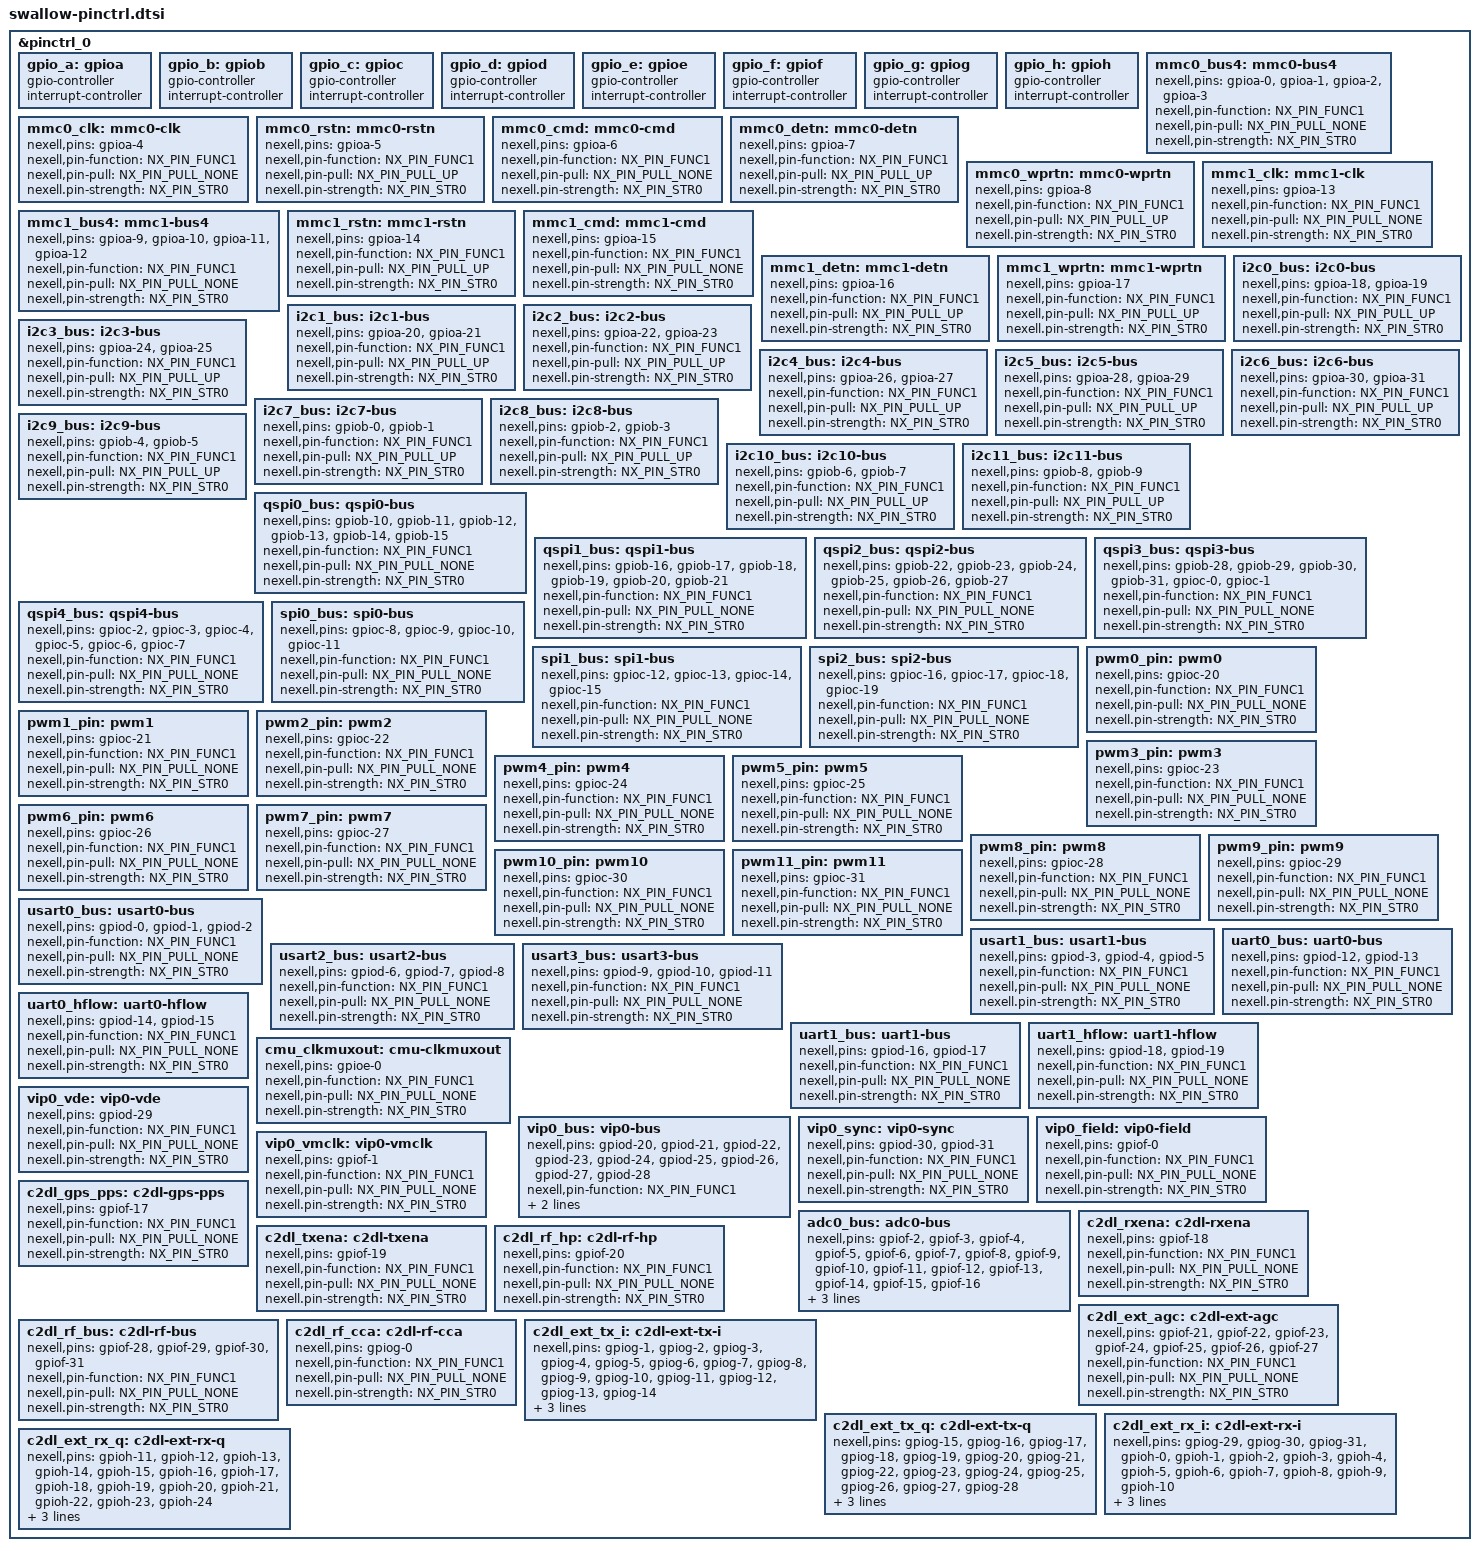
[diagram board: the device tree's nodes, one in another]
/*
 * SPDX-License-Identifier: (GPL-2.0+ OR MIT)
 *
 * Copyright (C) 2018  Nexell Co., Ltd.
 * Author: Sungwoo, Park <swpark@nexell.co.kr>
 */
 #include <dt-bindings/pinctrl/nexell.h>

 &pinctrl_0 {
	gpio_a: gpioa {
		gpio-controller;
		#gpio-cells = <2>;

		interrupt-controller;
		#interrupt-cells = <2>;
	};

	gpio_b: gpiob {
		gpio-controller;
		#gpio-cells = <2>;

		interrupt-controller;
		#interrupt-cells = <2>;
	};

	gpio_c: gpioc {
		gpio-controller;
		#gpio-cells = <2>;

		interrupt-controller;
		#interrupt-cells = <2>;
	};

	gpio_d: gpiod {
		gpio-controller;
		#gpio-cells = <2>;

		interrupt-controller;
		#interrupt-cells = <2>;
	};

	gpio_e: gpioe {
		gpio-controller;
		#gpio-cells = <2>;

		interrupt-controller;
		#interrupt-cells = <2>;
	};

	gpio_f: gpiof {
		gpio-controller;
		#gpio-cells = <2>;

		interrupt-controller;
		#interrupt-cells = <2>;
	};

	gpio_g: gpiog {
		gpio-controller;
		#gpio-cells = <2>;

		interrupt-controller;
		#interrupt-cells = <2>;
	};

	gpio_h: gpioh {
		gpio-controller;
		#gpio-cells = <2>;

		interrupt-controller;
		#interrupt-cells = <2>;
	};

	mmc0_bus4: mmc0-bus4 {
		nexell,pins = "gpioa-0", "gpioa-1", "gpioa-2", "gpioa-3";
		nexell,pin-function = <NX_PIN_FUNC1>;
		nexell,pin-pull = <NX_PIN_PULL_NONE>;
		nexell,pin-strength = <NX_PIN_STR0>;
	};

	mmc0_clk: mmc0-clk {
		nexell,pins = "gpioa-4";
		nexell,pin-function = <NX_PIN_FUNC1>;
		nexell,pin-pull = <NX_PIN_PULL_NONE>;
		nexell.pin-strength = <NX_PIN_STR0>;
	};

	mmc0_rstn: mmc0-rstn {
		nexell,pins = "gpioa-5";
		nexell,pin-function = <NX_PIN_FUNC1>;
		nexell,pin-pull = <NX_PIN_PULL_UP>;
		nexell.pin-strength = <NX_PIN_STR0>;
	};

	mmc0_cmd: mmc0-cmd {
		nexell,pins = "gpioa-6";
		nexell,pin-function = <NX_PIN_FUNC1>;
		nexell,pin-pull = <NX_PIN_PULL_NONE>;
		nexell.pin-strength = <NX_PIN_STR0>;
	};

	mmc0_detn: mmc0-detn {
		nexell,pins = "gpioa-7";
		nexell,pin-function = <NX_PIN_FUNC1>;
		nexell,pin-pull = <NX_PIN_PULL_UP>;
		nexell.pin-strength = <NX_PIN_STR0>;
	};

	mmc0_wprtn: mmc0-wprtn {
		nexell,pins = "gpioa-8";
		nexell,pin-function = <NX_PIN_FUNC1>;
		nexell,pin-pull = <NX_PIN_PULL_UP>;
		nexell.pin-strength = <NX_PIN_STR0>;
	};

	mmc1_bus4: mmc1-bus4 {
		nexell,pins = "gpioa-9", "gpioa-10", "gpioa-11", "gpioa-12";
		nexell,pin-function = <NX_PIN_FUNC1>;
		nexell,pin-pull = <NX_PIN_PULL_NONE>;
		nexell,pin-strength = <NX_PIN_STR0>;
	};

	mmc1_clk: mmc1-clk {
		nexell,pins = "gpioa-13";
		nexell,pin-function = <NX_PIN_FUNC1>;
		nexell,pin-pull = <NX_PIN_PULL_NONE>;
		nexell.pin-strength = <NX_PIN_STR0>;
	};

	mmc1_rstn: mmc1-rstn {
		nexell,pins = "gpioa-14";
		nexell,pin-function = <NX_PIN_FUNC1>;
		nexell,pin-pull = <NX_PIN_PULL_UP>;
		nexell.pin-strength = <NX_PIN_STR0>;
	};

	mmc1_cmd: mmc1-cmd {
		nexell,pins = "gpioa-15";
		nexell,pin-function = <NX_PIN_FUNC1>;
		nexell,pin-pull = <NX_PIN_PULL_NONE>;
		nexell.pin-strength = <NX_PIN_STR0>;
	};

	mmc1_detn: mmc1-detn {
		nexell,pins = "gpioa-16";
		nexell,pin-function = <NX_PIN_FUNC1>;
		nexell,pin-pull = <NX_PIN_PULL_UP>;
		nexell.pin-strength = <NX_PIN_STR0>;
	};

	mmc1_wprtn: mmc1-wprtn {
		nexell,pins = "gpioa-17";
		nexell,pin-function = <NX_PIN_FUNC1>;
		nexell,pin-pull = <NX_PIN_PULL_UP>;
		nexell.pin-strength = <NX_PIN_STR0>;
	};

	i2c0_bus: i2c0-bus {
		nexell,pins = "gpioa-18", "gpioa-19";
		nexell,pin-function = <NX_PIN_FUNC1>;
		nexell,pin-pull = <NX_PIN_PULL_UP>;
		nexell.pin-strength = <NX_PIN_STR0>;
	};

	i2c1_bus: i2c1-bus {
		nexell,pins = "gpioa-20", "gpioa-21";
		nexell,pin-function = <NX_PIN_FUNC1>;
		nexell,pin-pull = <NX_PIN_PULL_UP>;
		nexell.pin-strength = <NX_PIN_STR0>;
	};

	i2c2_bus: i2c2-bus {
		nexell,pins = "gpioa-22", "gpioa-23";
		nexell,pin-function = <NX_PIN_FUNC1>;
		nexell,pin-pull = <NX_PIN_PULL_UP>;
		nexell.pin-strength = <NX_PIN_STR0>;
	};

	i2c3_bus: i2c3-bus {
		nexell,pins = "gpioa-24", "gpioa-25";
		nexell,pin-function = <NX_PIN_FUNC1>;
		nexell,pin-pull = <NX_PIN_PULL_UP>;
		nexell.pin-strength = <NX_PIN_STR0>;
	};

	i2c4_bus: i2c4-bus {
		nexell,pins = "gpioa-26", "gpioa-27";
		nexell,pin-function = <NX_PIN_FUNC1>;
		nexell,pin-pull = <NX_PIN_PULL_UP>;
		nexell.pin-strength = <NX_PIN_STR0>;
	};

	i2c5_bus: i2c5-bus {
		nexell,pins = "gpioa-28", "gpioa-29";
		nexell,pin-function = <NX_PIN_FUNC1>;
		nexell,pin-pull = <NX_PIN_PULL_UP>;
		nexell.pin-strength = <NX_PIN_STR0>;
	};

	i2c6_bus: i2c6-bus {
		nexell,pins = "gpioa-30", "gpioa-31";
		nexell,pin-function = <NX_PIN_FUNC1>;
		nexell,pin-pull = <NX_PIN_PULL_UP>;
		nexell.pin-strength = <NX_PIN_STR0>;
	};

	i2c7_bus: i2c7-bus {
		nexell,pins = "gpiob-0", "gpiob-1";
		nexell,pin-function = <NX_PIN_FUNC1>;
		nexell,pin-pull = <NX_PIN_PULL_UP>;
		nexell.pin-strength = <NX_PIN_STR0>;
	};

	i2c8_bus: i2c8-bus {
		nexell,pins = "gpiob-2", "gpiob-3";
		nexell,pin-function = <NX_PIN_FUNC1>;
		nexell,pin-pull = <NX_PIN_PULL_UP>;
		nexell.pin-strength = <NX_PIN_STR0>;
	};

	i2c9_bus: i2c9-bus {
		nexell,pins = "gpiob-4", "gpiob-5";
		nexell,pin-function = <NX_PIN_FUNC1>;
		nexell,pin-pull = <NX_PIN_PULL_UP>;
		nexell.pin-strength = <NX_PIN_STR0>;
	};

	i2c10_bus: i2c10-bus {
		nexell,pins = "gpiob-6", "gpiob-7";
		nexell,pin-function = <NX_PIN_FUNC1>;
		nexell,pin-pull = <NX_PIN_PULL_UP>;
		nexell.pin-strength = <NX_PIN_STR0>;
	};

	i2c11_bus: i2c11-bus {
		nexell,pins = "gpiob-8", "gpiob-9";
		nexell,pin-function = <NX_PIN_FUNC1>;
		nexell,pin-pull = <NX_PIN_PULL_UP>;
		nexell.pin-strength = <NX_PIN_STR0>;
	};

	qspi0_bus: qspi0-bus {
		nexell,pins = "gpiob-10", "gpiob-11", "gpiob-12", "gpiob-13",
		"gpiob-14", "gpiob-15";
		nexell,pin-function = <NX_PIN_FUNC1>;
		nexell,pin-pull = <NX_PIN_PULL_NONE>;
		nexell.pin-strength = <NX_PIN_STR0>;
	};

	qspi1_bus: qspi1-bus {
		nexell,pins = "gpiob-16", "gpiob-17", "gpiob-18", "gpiob-19",
		"gpiob-20", "gpiob-21";
		nexell,pin-function = <NX_PIN_FUNC1>;
		nexell,pin-pull = <NX_PIN_PULL_NONE>;
		nexell.pin-strength = <NX_PIN_STR0>;
	};

	qspi2_bus: qspi2-bus {
		nexell,pins = "gpiob-22", "gpiob-23", "gpiob-24", "gpiob-25",
		"gpiob-26", "gpiob-27";
		nexell,pin-function = <NX_PIN_FUNC1>;
		nexell,pin-pull = <NX_PIN_PULL_NONE>;
		nexell.pin-strength = <NX_PIN_STR0>;
	};

	qspi3_bus: qspi3-bus {
		nexell,pins = "gpiob-28", "gpiob-29", "gpiob-30", "gpiob-31",
		"gpioc-0", "gpioc-1";
		nexell,pin-function = <NX_PIN_FUNC1>;
		nexell,pin-pull = <NX_PIN_PULL_NONE>;
		nexell.pin-strength = <NX_PIN_STR0>;
	};

	qspi4_bus: qspi4-bus {
		nexell,pins = "gpioc-2", "gpioc-3", "gpioc-4", "gpioc-5",
		"gpioc-6", "gpioc-7";
		nexell,pin-function = <NX_PIN_FUNC1>;
		nexell,pin-pull = <NX_PIN_PULL_NONE>;
		nexell.pin-strength = <NX_PIN_STR0>;
	};

	spi0_bus: spi0-bus {
		nexell,pins = "gpioc-8", "gpioc-9", "gpioc-10", "gpioc-11";
		nexell,pin-function = <NX_PIN_FUNC1>;
		nexell,pin-pull = <NX_PIN_PULL_NONE>;
		nexell.pin-strength = <NX_PIN_STR0>;
	};

	spi1_bus: spi1-bus {
		nexell,pins = "gpioc-12", "gpioc-13", "gpioc-14", "gpioc-15";
		nexell,pin-function = <NX_PIN_FUNC1>;
		nexell,pin-pull = <NX_PIN_PULL_NONE>;
		nexell.pin-strength = <NX_PIN_STR0>;
	};

	spi2_bus: spi2-bus {
		nexell,pins = "gpioc-16", "gpioc-17", "gpioc-18", "gpioc-19";
		nexell,pin-function = <NX_PIN_FUNC1>;
		nexell,pin-pull = <NX_PIN_PULL_NONE>;
		nexell.pin-strength = <NX_PIN_STR0>;
	};

	pwm0_pin: pwm0 {
		nexell,pins = "gpioc-20";
		nexell,pin-function = <NX_PIN_FUNC1>;
		nexell,pin-pull = <NX_PIN_PULL_NONE>;
		nexell.pin-strength = <NX_PIN_STR0>;
	};

	pwm1_pin: pwm1 {
		nexell,pins = "gpioc-21";
		nexell,pin-function = <NX_PIN_FUNC1>;
		nexell,pin-pull = <NX_PIN_PULL_NONE>;
		nexell.pin-strength = <NX_PIN_STR0>;
	};

	pwm2_pin: pwm2 {
		nexell,pins = "gpioc-22";
		nexell,pin-function = <NX_PIN_FUNC1>;
		nexell,pin-pull = <NX_PIN_PULL_NONE>;
		nexell.pin-strength = <NX_PIN_STR0>;
	};

	pwm3_pin: pwm3 {
		nexell,pins = "gpioc-23";
		nexell,pin-function = <NX_PIN_FUNC1>;
		nexell,pin-pull = <NX_PIN_PULL_NONE>;
		nexell.pin-strength = <NX_PIN_STR0>;
	};

	pwm4_pin: pwm4 {
		nexell,pins = "gpioc-24";
		nexell,pin-function = <NX_PIN_FUNC1>;
		nexell,pin-pull = <NX_PIN_PULL_NONE>;
		nexell.pin-strength = <NX_PIN_STR0>;
	};

	pwm5_pin: pwm5 {
		nexell,pins = "gpioc-25";
		nexell,pin-function = <NX_PIN_FUNC1>;
		nexell,pin-pull = <NX_PIN_PULL_NONE>;
		nexell.pin-strength = <NX_PIN_STR0>;
	};

	pwm6_pin: pwm6 {
		nexell,pins = "gpioc-26";
		nexell,pin-function = <NX_PIN_FUNC1>;
		nexell,pin-pull = <NX_PIN_PULL_NONE>;
		nexell.pin-strength = <NX_PIN_STR0>;
	};

	pwm7_pin: pwm7 {
		nexell,pins = "gpioc-27";
		nexell,pin-function = <NX_PIN_FUNC1>;
		nexell,pin-pull = <NX_PIN_PULL_NONE>;
		nexell.pin-strength = <NX_PIN_STR0>;
	};

	pwm8_pin: pwm8 {
		nexell,pins = "gpioc-28";
		nexell,pin-function = <NX_PIN_FUNC1>;
		nexell,pin-pull = <NX_PIN_PULL_NONE>;
		nexell.pin-strength = <NX_PIN_STR0>;
	};

	pwm9_pin: pwm9 {
		nexell,pins = "gpioc-29";
		nexell,pin-function = <NX_PIN_FUNC1>;
		nexell,pin-pull = <NX_PIN_PULL_NONE>;
		nexell.pin-strength = <NX_PIN_STR0>;
	};

	pwm10_pin: pwm10 {
		nexell,pins = "gpioc-30";
		nexell,pin-function = <NX_PIN_FUNC1>;
		nexell,pin-pull = <NX_PIN_PULL_NONE>;
		nexell.pin-strength = <NX_PIN_STR0>;
	};

	pwm11_pin: pwm11 {
		nexell,pins = "gpioc-31";
		nexell,pin-function = <NX_PIN_FUNC1>;
		nexell,pin-pull = <NX_PIN_PULL_NONE>;
		nexell.pin-strength = <NX_PIN_STR0>;
	};

	usart0_bus: usart0-bus {
		nexell,pins = "gpiod-0", "gpiod-1", "gpiod-2";
		nexell,pin-function = <NX_PIN_FUNC1>;
		nexell,pin-pull = <NX_PIN_PULL_NONE>;
		nexell.pin-strength = <NX_PIN_STR0>;
	};

	usart1_bus: usart1-bus {
		nexell,pins = "gpiod-3", "gpiod-4", "gpiod-5";
		nexell,pin-function = <NX_PIN_FUNC1>;
		nexell,pin-pull = <NX_PIN_PULL_NONE>;
		nexell.pin-strength = <NX_PIN_STR0>;
	};

	usart2_bus: usart2-bus {
		nexell,pins = "gpiod-6", "gpiod-7", "gpiod-8";
		nexell,pin-function = <NX_PIN_FUNC1>;
		nexell,pin-pull = <NX_PIN_PULL_NONE>;
		nexell.pin-strength = <NX_PIN_STR0>;
	};

	usart3_bus: usart3-bus {
		nexell,pins = "gpiod-9", "gpiod-10", "gpiod-11";
		nexell,pin-function = <NX_PIN_FUNC1>;
		nexell,pin-pull = <NX_PIN_PULL_NONE>;
		nexell.pin-strength = <NX_PIN_STR0>;
	};

	uart0_bus: uart0-bus {
		nexell,pins = "gpiod-12", "gpiod-13";
		nexell,pin-function = <NX_PIN_FUNC1>;
		nexell,pin-pull = <NX_PIN_PULL_NONE>;
		nexell.pin-strength = <NX_PIN_STR0>;
	};

	uart0_hflow: uart0-hflow {
		nexell,pins = "gpiod-14", "gpiod-15";
		nexell,pin-function = <NX_PIN_FUNC1>;
		nexell,pin-pull = <NX_PIN_PULL_NONE>;
		nexell.pin-strength = <NX_PIN_STR0>;
	};

	uart1_bus: uart1-bus {
		nexell,pins = "gpiod-16", "gpiod-17";
		nexell,pin-function = <NX_PIN_FUNC1>;
		nexell,pin-pull = <NX_PIN_PULL_NONE>;
		nexell.pin-strength = <NX_PIN_STR0>;
	};

	uart1_hflow: uart1-hflow {
		nexell,pins = "gpiod-18", "gpiod-19";
		nexell,pin-function = <NX_PIN_FUNC1>;
		nexell,pin-pull = <NX_PIN_PULL_NONE>;
		nexell.pin-strength = <NX_PIN_STR0>;
	};

	cmu_clkmuxout: cmu-clkmuxout {
		nexell,pins = "gpioe-0";
		nexell,pin-function = <NX_PIN_FUNC1>;
		nexell,pin-pull = <NX_PIN_PULL_NONE>;
		nexell.pin-strength = <NX_PIN_STR0>;
	};

	vip0_bus: vip0-bus {
		nexell,pins = "gpiod-20", "gpiod-21", "gpiod-22", "gpiod-23",
		"gpiod-24", "gpiod-25", "gpiod-26", "gpiod-27", "gpiod-28";
		nexell,pin-function = <NX_PIN_FUNC1>;
		nexell,pin-pull = <NX_PIN_PULL_NONE>;
		nexell.pin-strength = <NX_PIN_STR0>;
	};

	vip0_vde: vip0-vde {
		nexell,pins = "gpiod-29";
		nexell,pin-function = <NX_PIN_FUNC1>;
		nexell,pin-pull = <NX_PIN_PULL_NONE>;
		nexell.pin-strength = <NX_PIN_STR0>;
	};

	vip0_sync: vip0-sync {
		nexell,pins = "gpiod-30", "gpiod-31";
		nexell,pin-function = <NX_PIN_FUNC1>;
		nexell,pin-pull = <NX_PIN_PULL_NONE>;
		nexell.pin-strength = <NX_PIN_STR0>;
	};

	vip0_field: vip0-field {
		nexell,pins = "gpiof-0";
		nexell,pin-function = <NX_PIN_FUNC1>;
		nexell,pin-pull = <NX_PIN_PULL_NONE>;
		nexell.pin-strength = <NX_PIN_STR0>;
	};

	vip0_vmclk: vip0-vmclk {
		nexell,pins = "gpiof-1";
		nexell,pin-function = <NX_PIN_FUNC1>;
		nexell,pin-pull = <NX_PIN_PULL_NONE>;
		nexell.pin-strength = <NX_PIN_STR0>;
	};

	adc0_bus: adc0-bus {
		nexell,pins = "gpiof-2", "gpiof-3", "gpiof-4", "gpiof-5",
		"gpiof-6", "gpiof-7", "gpiof-8", "gpiof-9", "gpiof-10",
		"gpiof-11", "gpiof-12", "gpiof-13", "gpiof-14", "gpiof-15",
		"gpiof-16";
		nexell,pin-function = <NX_PIN_FUNC1>;
		nexell,pin-pull = <NX_PIN_PULL_NONE>;
		nexell.pin-strength = <NX_PIN_STR0>;
	};

	c2dl_gps_pps: c2dl-gps-pps {
		nexell,pins = "gpiof-17";
		nexell,pin-function = <NX_PIN_FUNC1>;
		nexell,pin-pull = <NX_PIN_PULL_NONE>;
		nexell.pin-strength = <NX_PIN_STR0>;
	};

	c2dl_rxena: c2dl-rxena {
		nexell,pins = "gpiof-18";
		nexell,pin-function = <NX_PIN_FUNC1>;
		nexell,pin-pull = <NX_PIN_PULL_NONE>;
		nexell.pin-strength = <NX_PIN_STR0>;
	};

	c2dl_txena: c2dl-txena {
		nexell,pins = "gpiof-19";
		nexell,pin-function = <NX_PIN_FUNC1>;
		nexell,pin-pull = <NX_PIN_PULL_NONE>;
		nexell.pin-strength = <NX_PIN_STR0>;
	};

	c2dl_rf_hp: c2dl-rf-hp {
		nexell,pins = "gpiof-20";
		nexell,pin-function = <NX_PIN_FUNC1>;
		nexell,pin-pull = <NX_PIN_PULL_NONE>;
		nexell.pin-strength = <NX_PIN_STR0>;
	};

	c2dl_ext_agc: c2dl-ext-agc {
		nexell,pins = "gpiof-21", "gpiof-22", "gpiof-23", "gpiof-24",
		"gpiof-25", "gpiof-26", "gpiof-27";
		nexell,pin-function = <NX_PIN_FUNC1>;
		nexell,pin-pull = <NX_PIN_PULL_NONE>;
		nexell.pin-strength = <NX_PIN_STR0>;
	};

	c2dl_rf_bus: c2dl-rf-bus {
		nexell,pins = "gpiof-28", "gpiof-29", "gpiof-30", "gpiof-31";
		nexell,pin-function = <NX_PIN_FUNC1>;
		nexell,pin-pull = <NX_PIN_PULL_NONE>;
		nexell.pin-strength = <NX_PIN_STR0>;
	};

	c2dl_rf_cca: c2dl-rf-cca {
		nexell,pins = "gpiog-0";
		nexell,pin-function = <NX_PIN_FUNC1>;
		nexell,pin-pull = <NX_PIN_PULL_NONE>;
		nexell.pin-strength = <NX_PIN_STR0>;
	};

	c2dl_ext_tx_i: c2dl-ext-tx-i {
		nexell,pins = "gpiog-1", "gpiog-2", "gpiog-3", "gpiog-4",
		"gpiog-5", "gpiog-6", "gpiog-7", "gpiog-8", "gpiog-9",
		"gpiog-10", "gpiog-11", "gpiog-12", "gpiog-13", "gpiog-14";
		nexell,pin-function = <NX_PIN_FUNC1>;
		nexell,pin-pull = <NX_PIN_PULL_NONE>;
		nexell.pin-strength = <NX_PIN_STR0>;
	};

	c2dl_ext_tx_q: c2dl-ext-tx-q {
		nexell,pins = "gpiog-15", "gpiog-16", "gpiog-17", "gpiog-18",
		"gpiog-19", "gpiog-20", "gpiog-21", "gpiog-22", "gpiog-23",
		"gpiog-24", "gpiog-25", "gpiog-26", "gpiog-27", "gpiog-28";
		nexell,pin-function = <NX_PIN_FUNC1>;
		nexell,pin-pull = <NX_PIN_PULL_NONE>;
		nexell.pin-strength = <NX_PIN_STR0>;
	};

	c2dl_ext_rx_i: c2dl-ext-rx-i {
		nexell,pins = "gpiog-29", "gpiog-30", "gpiog-31", "gpioh-0",
		"gpioh-1", "gpioh-2", "gpioh-3", "gpioh-4", "gpioh-5",
		"gpioh-6", "gpioh-7", "gpioh-8", "gpioh-9", "gpioh-10";
		nexell,pin-function = <NX_PIN_FUNC1>;
		nexell,pin-pull = <NX_PIN_PULL_NONE>;
		nexell.pin-strength = <NX_PIN_STR0>;
	};

	c2dl_ext_rx_q: c2dl-ext-rx-q {
		nexell,pins = "gpioh-11", "gpioh-12", "gpioh-13", "gpioh-14",
		"gpioh-15", "gpioh-16", "gpioh-17", "gpioh-18", "gpioh-19",
		"gpioh-20", "gpioh-21", "gpioh-22", "gpioh-23", "gpioh-24";
		nexell,pin-function = <NX_PIN_FUNC1>;
		nexell,pin-pull = <NX_PIN_PULL_NONE>;
		nexell.pin-strength = <NX_PIN_STR0>;
	};
 };
